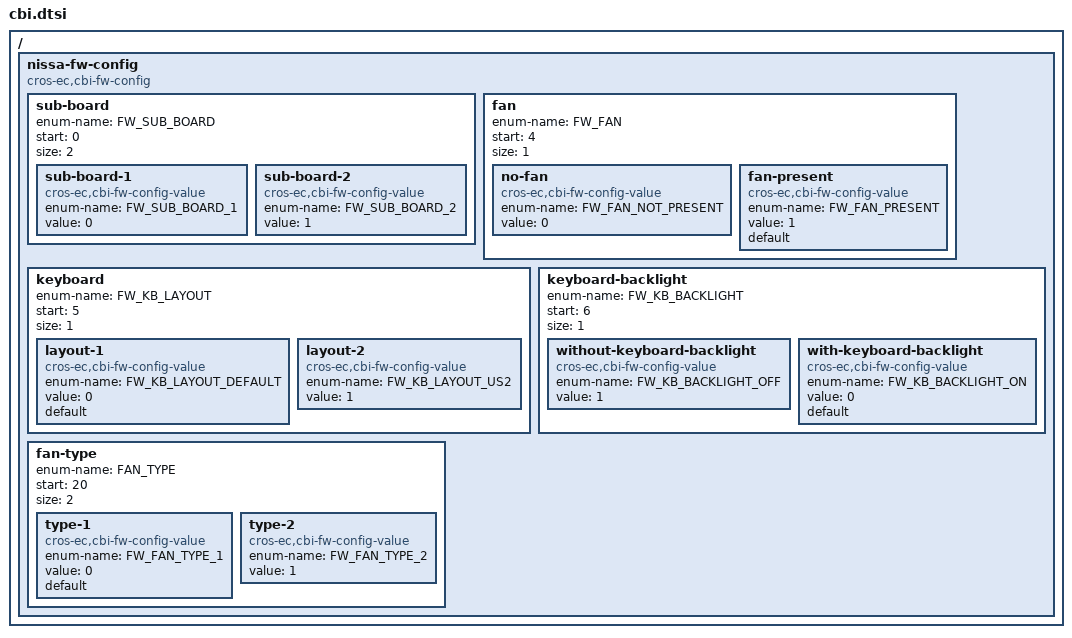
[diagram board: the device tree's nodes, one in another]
/* Copyright 2024 The ChromiumOS Authors
 * Use of this source code is governed by a BSD-style license that can be
 * found in the LICENSE file.
 */

/ {
	/* Yavista-specific fw_config fields. */
	nissa-fw-config {
		compatible = "cros-ec,cbi-fw-config";
		/*
		 * FW_CONFIG field to indicate which sub-board
		 * is attached.
		 */
		sub-board {
			enum-name = "FW_SUB_BOARD";
			start = <0>;
			size = <2>;

			sub-board-1 {
				compatible = "cros-ec,cbi-fw-config-value";
				enum-name = "FW_SUB_BOARD_1";
				value = <0>;
			};
			sub-board-2 {
				compatible = "cros-ec,cbi-fw-config-value";
				enum-name = "FW_SUB_BOARD_2";
				value = <1>;
			};
		};

		/*
		 * FW_CONFIG field for multiple wi-fi SAR.
		 *
		 *	start = <2>;
		 *	size = <2>;
		 */

		/*
		 * FW_CONFIG field to enable fan or not.
		 */
		fan {
			enum-name = "FW_FAN";
			start = <4>;
			size = <1>;

			no-fan {
				compatible = "cros-ec,cbi-fw-config-value";
				enum-name = "FW_FAN_NOT_PRESENT";
				value = <0>;
			};
			fan-present {
				compatible = "cros-ec,cbi-fw-config-value";
				enum-name = "FW_FAN_PRESENT";
				value = <1>;
				/*
				 * Set as default so that unprovisioned
				 * configs will run the fan regardless.
				 */
				default;
			};
		};

		/*
		 * FW_CONFIG field to indicate which keyboard layout
		 * should be used.
		 */
		keyboard {
			enum-name = "FW_KB_LAYOUT";
			start = <5>;
			size = <1>;

			layout-1 {
				compatible = "cros-ec,cbi-fw-config-value";
				enum-name = "FW_KB_LAYOUT_DEFAULT";
				value = <0>;
				default;
			};
			layout-2 {
				compatible = "cros-ec,cbi-fw-config-value";
				enum-name = "FW_KB_LAYOUT_US2";
				value = <1>;
			};
		};

		/*
		 * FW_CONFIG field to indicate which keyboard layout
		 * should be used.
		 */
		keyboard-backlight {
			enum-name = "FW_KB_BACKLIGHT";
			start = <6>;
			size = <1>;

			without-keyboard-backlight {
				compatible = "cros-ec,cbi-fw-config-value";
				enum-name = "FW_KB_BACKLIGHT_OFF";
				value = <1>;
			};
			with-keyboard-backlight {
				compatible = "cros-ec,cbi-fw-config-value";
				enum-name = "FW_KB_BACKLIGHT_ON";
				value = <0>;
				default;
			};
		};

		/*
		 * FW_CONFIG field for multiple touch panel.
		 *
		 *	start = <7>;
		 *	size = <2>;
		 */

		/*
		 * FW_CONFIG field to indicate which fan type
		 * should be used.
		 */
		fan-type {
			enum-name = "FAN_TYPE";
			start = <20>;
			size = <2>;

			type-1 {
				compatible = "cros-ec,cbi-fw-config-value";
				enum-name = "FW_FAN_TYPE_1";
				value = <0>;
				default;
			};
			type-2 {
				compatible = "cros-ec,cbi-fw-config-value";
				enum-name = "FW_FAN_TYPE_2";
				value = <1>;
			};
		};

		/*
		 * FW_CONFIG field for multiple storage.
		 *
		 *	start = <31>;
		 *	size = <1>;
		 */
	};
};
